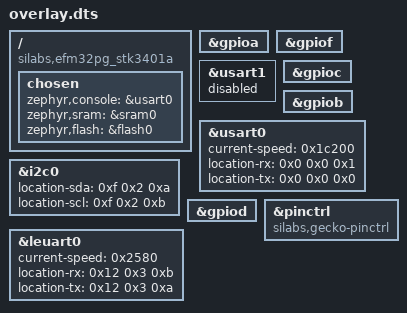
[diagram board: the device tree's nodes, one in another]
/ {
	compatible = "silabs,efm32pg_stk3401a", "silabs,efm32pg1b";
	chosen {
		zephyr,console = &usart0;
		zephyr,sram = &sram0;
		zephyr,flash = &flash0;
	};
};
&gpioa{
	status = "okay";
};
&gpiof{
	status = "okay";
};
&usart1{
	status = "disabled";
};
&gpioc{
	status = "okay";
};
&gpiob{
	status = "okay";
};
&usart0{
	status = "okay";
	current-speed = < 0x1c200 >;
	location-rx = < 0x0 0x0 0x1 >;
	location-tx = < 0x0 0x0 0x0 >;
};
&i2c0{
	status = "okay";
	location-sda = < 0xf 0x2 0xa >;
	location-scl = < 0xf 0x2 0xb >;
};
&gpiod{
	status = "okay";
};
&leuart0{
	status = "okay";
	current-speed = < 0x2580 >;
	location-rx = < 0x12 0x3 0xb >;
	location-tx = < 0x12 0x3 0xa >;
};
&pinctrl{
	compatible = "silabs,gecko-pinctrl";
};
